# RT58X register map
Series: ARMv8-M Mainline; File version: 1.0
CPU: CM3 r0p0, little endian, MPU, no FPU, VTOR, 3 interrupt priority bits
Registers are 32-bit, read-write, reset 0x0 unless marked. A register's access mark holds for its fields unless they carry their own. Offsets are from the block's base; [hi:lo] are bit positions; {n}, {i} and the like mark numbered series.

## QSPI0 — QSPI0 Register block
Base 0xB0000000
0x00 QSPI_TX_REG — Serial Transmit Data Register
0x04 QSPI_RX_REG ro — Serial Receive Data Register
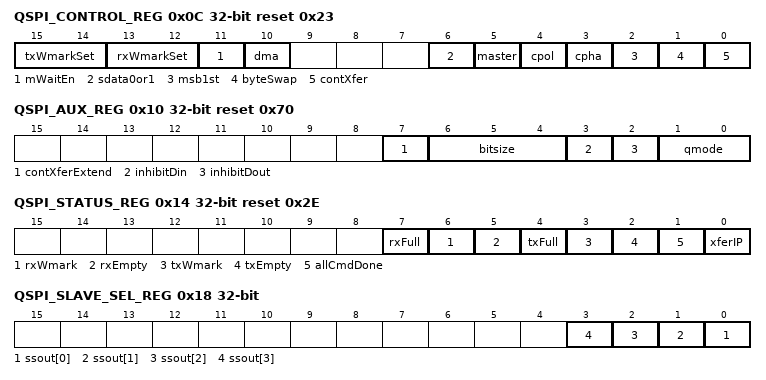
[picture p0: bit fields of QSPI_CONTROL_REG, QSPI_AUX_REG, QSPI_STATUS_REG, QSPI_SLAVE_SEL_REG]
0x0C QSPI_CONTROL_REG reset 0x23 — qspi control
  [15:14] txWmarkSet — Sets the Watermark Level for TX FIFO operation, QSPI_FIFO_DEPTH=32 0: QSPI_FIFO_DEPTH/8 1: QSPI_FIFO_DEPTH/4 2: QSPI_FIFO_DEPTH/2 3: QSPI_FIFO_DEPTH/2+QSPI_FIFO_DEPTH/4
    0=B_14_to_15 (Sets the Watermark Level for TX FIFO operation, QSPI_FIFO_DEPTH=32 0: QSPI_FIFO_DEPTH/8 1: QSPI_FIFO_DEPTH/4 2: QSPI_FIFO_DEPTH/2 3: QSPI_FIFO_DEPTH/2+QSPI_FIFO_DEPTH/4)
  [13:12] rxWmarkSet — Sets the Watermark Level for RX FIFO operation, QSPI_FIFO_DEPTH=32 0: QSPI_FIFO_DEPTH/8 1: QSPI_FIFO_DEPTH/4 2: QSPI_FIFO_DEPTH/2 3: QSPI_FIFO_DEPTH/2+QSPI_FIFO_DEPTH/4
    0=B_12_to_13 (Sets the Watermark Level for RX FIFO operation, QSPI_FIFO_DEPTH=32 0: QSPI_FIFO_DEPTH/8 1: QSPI_FIFO_DEPTH/4 2: QSPI_FIFO_DEPTH/2 3: QSPI_FIFO_DEPTH/2+QSPI_FIFO_DEPTH/4)
  [11] mWaitEn — Inter-transfer delay for Master operation. 0: disable delay (full speed), 1: enable delay.
    0=B_11 (Inter-transfer delay for Master operation. 0: disable delay (full speed), 1: enable delay.)
  [10] dma — N/C in the design.
    0=B_10 (N/C in the design.)
  [6] sdata0or1 — In normal SPI mode, set 0 for master and set 1 for slave. 0: SDATA[0]=sdata_out[0], sdata_in[0]=SDATA[1]. 1: SDATA[1]=sdata_out[0], sdata_in[0]=SDATA[0].
    0=B_6 (In normal SPI mode, set 0 for master and set 1 for slave. 0: SDATA[0]=sdata_out[0], sdata_in[0]=SDATA[1]. 1: SDATA[1]=sdata_out[0], sdata_in[0]=SDATA[0].)
  [5] master — SPI port bus master mode of operation; 0: slave mode 1: master mode
    0=B_5 (SPI port bus master mode of operation; 0: slave mode 1: master mode)
  [4] cpol — 0: SPI clock rests low 1: SPI clock rests high
    0=B_4 (0: SPI clock rests low 1: SPI clock rests high)
  [3] cpha — 0: first bit(s) of sdataOut occur as SS is asserted. 1: sdataOut occurs on first SPI clock edge after SS.
    0=B_3 (0: first bit(s) of sdataOut occur as SS is asserted. 1: sdataOut occurs on first SPI clock edge after SS.)
  [2] msb1st — MSB/LSB 1=MSB first, 0=LSB first
    0=B_2 (MSB/LSB 1=MSB first, 0=LSB first)
  [1] byteSwap — Byte swap in bitsize = 16/32 bit for TX/RX FIFO.
    0=B_1 (Byte swap in bitsize = 16/32 bit for TX/RX FIFO.)
  [0] contXfer — Continuous Transfer bit. This is relevant for Master operation only.
    0=B_0 (Continuous Transfer bit. This is relevant for Master operation only.)
0x10 QSPI_AUX_REG reset 0x70 — qspi aux
  [7] contXferExtend — Continuous Transfer Extend Bit. This is relevant for Master operation only. Further, this bit has no effect if the contXfer bit is 0. This register bit is synchronized to the SCLK domain for use there. Note that this setting also affects the timing of the master output enable signal, sdataOutEnMN. Set to 1 to have ssOut[x] remain active even when the TX FIFO is empty. Set to 0 to have ssOut[x] become inactive when the TX FIFO is empty.
    0=B_7 (Continuous Transfer Extend Bit. This is relevant for Master operation only. Further, this bit has no effect if the contXfer bit is 0. This register bit is synchronized to the SCLK domain for use there. Note that this setting also affects the timing of the master output enable signal, sdataOutEnMN. Set to 1 to have ssOut[x] remain active even when the TX FIFO is empty. Set to 0 to have ssOut[x] become inactive when the TX FIFO is empty.)
  [6:4] bitsize — Bitsize = (#bits in transfer+1)*4. For example: 0: 4 bit serial mode, 1: 8 bit serial mode, 2: 12 bit serial mode, 3: 16 bit serial mode, 4: 20 bit serial mode, 5: 24 bit serial mode, 6: 28 bit serial mode, 7: 32 bit serial mode
    0=B_4_to_6 (Bitsize = (#bits in transfer+1)*4. For example: 0: 4 bit serial mode, 1: 8 bit serial mode, 2: 12 bit serial mode, 3: 16 bit serial mode, 4: 20 bit serial mode, 5: 24 bit serial mode, 6: 28 bit serial mode, 7: 32 bit serial mode)
  [3] inhibitDin — Set to 1 to inhibit the SPI serializers from writing to the Read Data FIFO.
    0=B_3 (Set to 1 to inhibit the SPI serializers from writing to the Read Data FIFO.)
  [2] inhibitDout — Set to 1 to inhibit the SPI serializers from reading the Transmit FIFO.
    0=B_2 (Set to 1 to inhibit the SPI serializers from reading the Transmit FIFO.)
  [1:0] qmode — Spi Modes: 0: Normal SPI 1: Reserved 2: Dual SPI 3: Quad SPI
    0=B_0_to_1 (Spi Modes: 0: Normal SPI 1: Reserved 2: Dual SPI 3: Quad SPI)
0x14 QSPI_STATUS_REG ro reset 0x2E — qspi status
  [7] rxFull — Receive FIFO full flag
    0=B_7 (Receive FIFO full flag)
  [6] rxWmark — Receive FIFO watermark flag
    0=B_6 (Receive FIFO watermark flag)
  [5] rxEmpty — Receive FIFO empty flag
    0=B_5 (Receive FIFO empty flag)
  [4] txFull — Transmit FIFO full flag
    0=B_4 (Transmit FIFO full flag)
  [3] txWmark — Transmit FIFO watermark flag
    0=B_3 (Transmit FIFO watermark flag)
  [2] txEmpty — Transmit FIFO empty flag
    0=B_2 (Transmit FIFO empty flag)
  [1] allCmdDone — txEmpty & !xferIP
    0=B_1 (txEmpty & !xferIP)
  [0] xferIP — Transfer is in progress (ssOut/ssIn is active)
    0=B_0 (Transfer is in progress (ssOut/ssIn is active))
0x18 QSPI_SLAVE_SEL_REG — qspi slave sel
  [n] ssout[{n}] (n=0..3) — 0: Do not select slave {n} for TX/RX. 1: Select Slave {n} for TX/RX.
    0=B_{n} (0: Do not select slave {n} for TX/RX. 1: Select Slave {n} for TX/RX.)
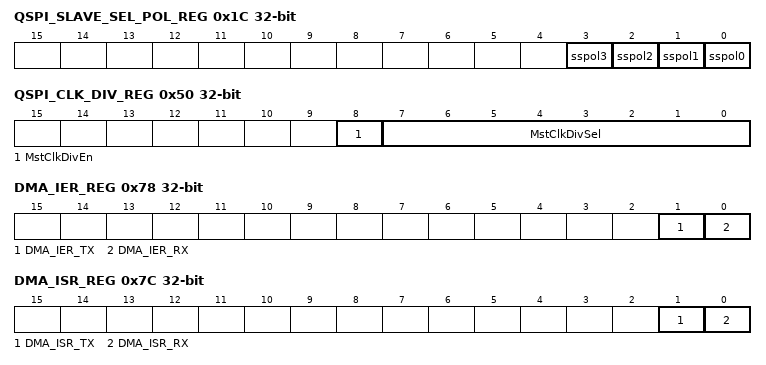
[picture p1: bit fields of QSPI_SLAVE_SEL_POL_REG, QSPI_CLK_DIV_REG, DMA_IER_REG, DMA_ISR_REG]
0x1C QSPI_SLAVE_SEL_POL_REG — qspi slave sel pol
  [3] sspol3 — 0: ssOut[3] (Master) is an active low signal 1: ssOut[3] (Master) is an active high signal
    0=B_3 (0: ssOut[3] (Master) is an active low signal 1: ssOut[3] (Master) is an active high signal)
  [2] sspol2 — 0: ssOut[2] (Master) is an active low signal 1: ssOut[2] (Master) is an active high signal
    0=B_2 (0: ssOut[2] (Master) is an active low signal 1: ssOut[2] (Master) is an active high signal)
  [1] sspol1 — 0: ssOut[1] (Master) is an active low signal 1: ssOut[1] (Master) is an active high signal
    0=B_1 (0: ssOut[1] (Master) is an active low signal 1: ssOut[1] (Master) is an active high signal)
  [0] sspol0 — 0: ssOut[0] (Master) or ssIn (Slave) is an active low signal 1: ssOut[0] (Master) or ssIn (Slave) is an active high signal
    0=B_0 (0: ssOut[0] (Master) or ssIn (Slave) is an active low signal 1: ssOut[0] (Master) or ssIn (Slave) is an active high signal)
0x20 QSPI_INTR_EN_REG — qspi intr en
  [5:0] intrEnable — Write 1 to enable individual interrupts (see Interrupt Mapping). A read will return a status of the enabled interrupts.
    0=B_0_to_5 (Write 1 to enable individual interrupts (see Interrupt Mapping). A read will return a status of the enabled interrupts.)
0x24 QSPI_INTR_STATUS_REG ro — qspi intr status
  [5:0] intrStatus — Interrupt Status 0: no interrupt 1: interrupt source is active,
    0=B_0_to_5 (Interrupt Status 0: no interrupt 1: interrupt source is active,)
0x28 QSPI_INTR_CLR_REG — qspi intr clr
  [5:0] intrClear wo — Clear Interrupt Writing a 1 clears the interrupt bit. Writing a 0 has no effect.
    0=B_0_to_5 (Clear Interrupt Writing a 1 clears the interrupt bit. Writing a 0 has no effect.)
0x2C QSPI_TX_FIFO_LVL_REG ro — qspi tx fifo lvl
  [6:0] tx_FIFO_level — Read transmit FIFO current level (0-32).
    0=B_0_to_6 (Read transmit FIFO current level (0-32).)
0x30 QSPI_RX_FIFO_LVL_REG ro — qspi rx fifo lvl
  [6:0] rx_FIFO_level — Read receive FIFO current level (0-32).
    0=B_0_to_6 (Read receive FIFO current level (0-32).)
0x38 QSPI_M_WAIT_REG — qspi m wait
  [7:0] mWait — If master (Control Register) is 1, this register sets the inter-transfer delay for the master serializer. The delay is (mwait+1) SCLK cycles.
    0=B_0_to_7 (If master (Control Register) is 1, this register sets the inter-transfer delay for the master serializer. The delay is (mwait+1) SCLK cycles.)
0x3C QSPI_EN_REG — qspi en
  [0] enable — SPI enable 0: Disable SPI TX and RX; reset RX and TX FIFOs on the transition from 1 to 0 of this bit. 1: Enable SPI TX and RX.
    0=B_0 (SPI enable 0: Disable SPI TX and RX; reset RX and TX FIFOs on the transition from 1 to 0 of this bit. 1: Enable SPI TX and RX.)
0x50 QSPI_CLK_DIV_REG — qspi clk div
  [8] MstClkDivEn — Master clock divider enable 0: Master clock = 32 MHz 1: Master clock = clock selected by MstClkDivSel.
    0=B_8 (Master clock divider enable 0: Master clock = 32 MHz 1: Master clock = clock selected by MstClkDivSel.)
  [7:0] MstClkDivSel — Master clock divider select. The master clock will be 16/(MstClkDivSel+1) MHz
    0=B_0_to_7 (Master clock divider select. The master clock will be 16/(MstClkDivSel+1) MHz)
0x60 DMA_RX_START_REG — DMA RX start address.
0x64 DMA_RX_LEN_REG — dma rx len
  [15:0] DMA_RX_Len — DMA RX length.
0x68 DMA_TX_START_REG — DMA TX start address.
0x6C DMA_TX_LEN_REG — dma tx len
  [15:0] DMA_TX_Len — DMA TX length.
0x70 DMA_RX_REMAINLEN_REG — dma rx remainlen
  [15:0] DMA_RX_RemainLen — xDMA transfer byte length remaining for RX
0x74 DMA_TX_REMAINLEN_REG — dma tx remainlen
  [15:0] DMA_TX_RemainLen — xDMA transfer byte length remaining for TX
0x78 DMA_IER_REG — dma ier
  [1] DMA_IER_TX — Interrupt enable for xDMA TX
    0=B_1 (Interrupt enable for xDMA TX)
  [0] DMA_IER_RX — Interrupt enable for xDMA RX
    0=B_0 (Interrupt enable for xDMA RX)
0x7C DMA_ISR_REG wo — dma isr
  [1] DMA_ISR_TX — Interrupt status for xDMA TX
    0=B_1 (Interrupt status for xDMA TX)
  [0] DMA_ISR_RX — Interrupt status for xDMA RX
    0=B_0 (Interrupt status for xDMA RX)
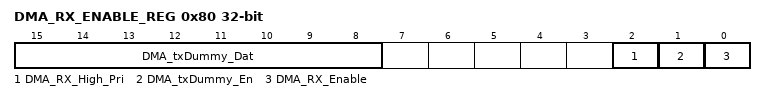
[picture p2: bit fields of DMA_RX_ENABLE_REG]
0x80 DMA_RX_ENABLE_REG — dma rx enable
  [15:8] DMA_txDummy_Dat — Dummy data for “DMA_txDummy_En”
    0=B_8_to_15 (Dummy data for “DMA_txDummy_En”)
  [2] DMA_RX_High_Pri — Enable to force both QSPI0 & QSPI1 RX DMA requests having higher priority than TX DMA requests in the AHB arbiter. Note: this bit is only valid at QSPI0 register space.
    0=B_2 (Enable to force both QSPI0 & QSPI1 RX DMA requests having higher priority than TX DMA requests in the AHB arbiter. Note: this bit is only valid at QSPI0 register space.)
  [1] DMA_txDummy_En — Enable to fill the TX FIFO with dummy data for master RX. Write 0 for completion or abort.
    0=B_1 (Enable to fill the TX FIFO with dummy data for master RX. Write 0 for completion or abort.)
  [0] DMA_RX_Enable — DMA rx enable. 0: Disable UART DMA RX. 1: Enable UART DMA RX.
    0=B_0 (DMA rx enable. 0: Disable UART DMA RX. 1: Enable UART DMA RX.)
0x84 DMA_TX_ENABLE_REG — dma tx enable
  [0] DMA_TX_Enable — DMA tx enable. 0: Disable UART DMA TX. 1: Enable UART DMA TX.
    0=B_0 (DMA tx enable. 0: Disable UART DMA TX. 1: Enable UART DMA TX.)
